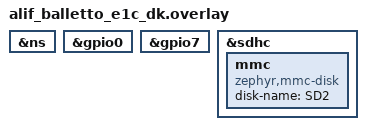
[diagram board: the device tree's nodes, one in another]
/*
 * Copyright (c) 2026 Alif Semiconductor.
 * SPDX-License-Identifier: Apache-2.0
 */

ns: &ns {
	status = "okay";
};

/* GPIO0 is needed for SDHC sd-vsel regulator */
&gpio0 {
	status = "okay";
};

/* GPIO7 is needed for SDHC sd-pwr regulator */
&gpio7 {
	status = "okay";
};

sdhc: &sdhc {
	status = "okay";
	/* eMMC is always present — no card-detect GPIO needed */
	/delete-property/ cd-gpios;

	mmc {
		compatible = "zephyr,mmc-disk";
		disk-name = "SD2";
		status = "okay";
	};
};
